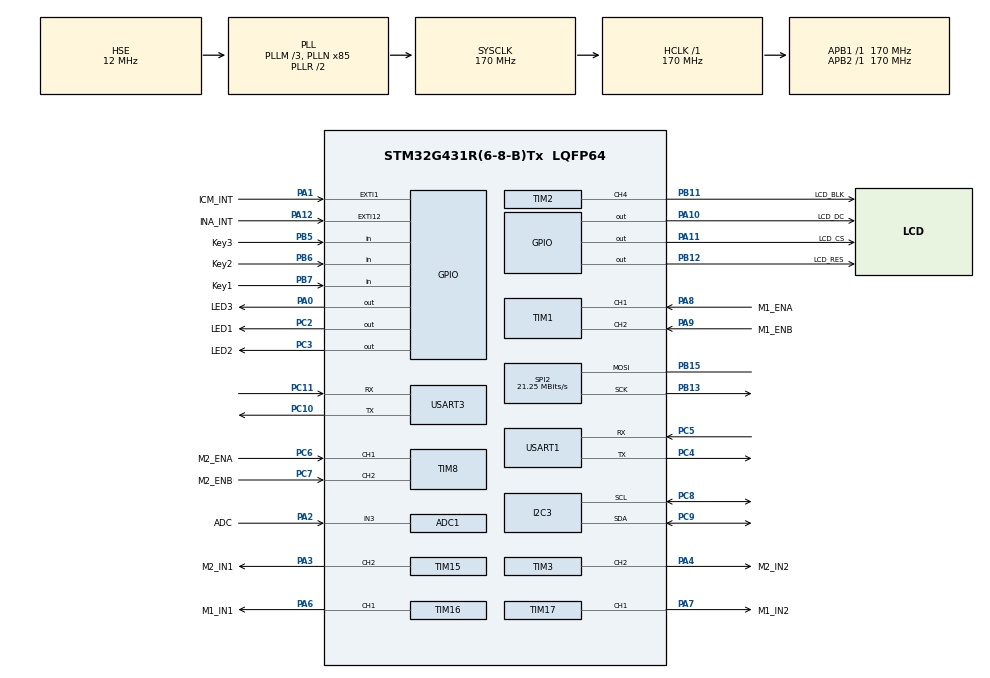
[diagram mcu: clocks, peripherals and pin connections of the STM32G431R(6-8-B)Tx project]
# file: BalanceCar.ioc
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ADC1.Channel-1\#ChannelRegularConversion=ADC_CHANNEL_3
ADC1.NbrOfConversionFlag=1
ADC1.OffsetNumber-1\#ChannelRegularConversion=ADC_OFFSET_NONE
ADC1.Rank-1\#ChannelRegularConversion=1
ADC1.SamplingTime-1\#ChannelRegularConversion=ADC_SAMPLETIME_2CYCLES_5
ADC1.master=1
I2C3.Timing=0x40B285C2
Mcu.Family=STM32G4
Mcu.Name=STM32G431R(6-8-B)Tx
Mcu.Package=LQFP64
NVIC.EXTI15_10_IRQn=true\:1\:0\:true\:false\:true\:true\:true\:true
NVIC.EXTI1_IRQn=true\:1\:0\:true\:false\:true\:true\:true\:true
NVIC.PriorityGroup=NVIC_PRIORITYGROUP_4
PA0.GPIO_Label=LED3
PA0.Signal=GPIO_Output
PA1.GPIO_Label=ICM_INT
PA1.Signal=GPXTI1
PA10.GPIO_Label=LCD_DC
PA10.Signal=GPIO_Output
PA11.GPIO_Label=LCD_CS
PA11.Signal=GPIO_Output
PA12.GPIO_Label=INA_INT
PA12.Signal=GPXTI12
PA13.Mode=Serial_Wire
PA13.Signal=SYS_JTMS-SWDIO
PA14.Mode=Serial_Wire
PA14.Signal=SYS_JTCK-SWCLK
PA2.GPIO_Label=ADC
PA2.Mode=IN3-Single-Ended
PA2.Signal=ADC1_IN3
PA3.GPIO_Label=M2_IN1
PA3.Signal=S_TIM15_CH2
PA4.GPIO_Label=M2_IN2
PA4.Signal=S_TIM3_CH2
PA6.GPIO_Label=M1_IN1
PA6.Signal=S_TIM16_CH1
PA7.GPIO_Label=M1_IN2
PA7.Signal=S_TIM17_CH1
PA8.GPIO_Label=M1_ENA
PA8.Signal=S_TIM1_CH1
PA9.GPIO_Label=M1_ENB
PA9.Signal=S_TIM1_CH2
PB11.GPIO_Label=LCD_BLK
PB11.Signal=S_TIM2_CH4
PB12.GPIO_Label=LCD_RES
PB12.Signal=GPIO_Output
PB13.Mode=Simplex_Bidirectional_Master
PB13.Signal=SPI2_SCK
PB15.Mode=Simplex_Bidirectional_Master
PB15.Signal=SPI2_MOSI
PB5.GPIO_Label=Key3
PB5.GPIO_PuPd=GPIO_PULLUP
PB5.Signal=GPIO_Input
PB6.GPIO_Label=Key2
PB6.GPIO_PuPd=GPIO_PULLUP
PB6.Signal=GPIO_Input
PB7.GPIO_Label=Key1
PB7.GPIO_PuPd=GPIO_PULLUP
PB7.Signal=GPIO_Input
PC10.Mode=Asynchronous
PC10.Signal=USART3_TX
PC11.Mode=Asynchronous
PC11.Signal=USART3_RX
PC2.GPIO_Label=LED1
PC2.Signal=GPIO_Output
PC3.GPIO_Label=LED2
PC3.Signal=GPIO_Output
PC4.Mode=Asynchronous
PC4.Signal=USART1_TX
PC5.Mode=Asynchronous
PC5.Signal=USART1_RX
PC6.GPIO_Label=M2_ENA
PC6.Signal=S_TIM8_CH1
PC7.GPIO_Label=M2_ENB
PC7.Signal=S_TIM8_CH2
PC8.Mode=I2C
PC8.Signal=I2C3_SCL
PC9.Mode=I2C
PC9.Signal=I2C3_SDA
PF0-OSC_IN.Mode=HSE-External-Oscillator
PF0-OSC_IN.Signal=RCC_OSC_IN
PF1-OSC_OUT.Mode=HSE-External-Oscillator
PF1-OSC_OUT.Signal=RCC_OSC_OUT
ProjectManager.HeapSize=0x200
ProjectManager.StackSize=0x400
ProjectManager.TargetToolchain=MDK-ARM V5.32
RCC.ADC12Freq_Value=170000000
RCC.AHBFreq_Value=170000000
RCC.APB1Freq_Value=170000000
RCC.APB1TimFreq_Value=170000000
RCC.APB2Freq_Value=170000000
RCC.APB2TimFreq_Value=170000000
RCC.CortexFreq_Value=170000000
RCC.EXTERNAL_CLOCK_VALUE=12288000
RCC.HCLKFreq_Value=170000000
RCC.HSE_VALUE=12000000
RCC.HSI48_VALUE=48000000
RCC.HSI_VALUE=16000000
RCC.LSE_VALUE=32768
RCC.PLLM=RCC_PLLM_DIV3
RCC.PLLN=85
RCC.PLLSourceVirtual=RCC_PLLSOURCE_HSE
RCC.SYSCLKFreq_VALUE=170000000
RCC.SYSCLKSource=RCC_SYSCLKSOURCE_PLLCLK
RCC.USBFreq_Value=170000000
RCC.VCOOutputFreq_Value=340000000
SH.S_TIM15_CH2.0=TIM15_CH2,PWM Generation2 CH2
SH.S_TIM16_CH1.0=TIM16_CH1,PWM Generation1 CH1
SH.S_TIM17_CH1.0=TIM17_CH1,PWM Generation1 CH1
SH.S_TIM1_CH1.0=TIM1_CH1,Encoder_Interface
SH.S_TIM1_CH2.0=TIM1_CH2,Encoder_Interface
SH.S_TIM2_CH4.0=TIM2_CH4,PWM Generation4 CH4
SH.S_TIM3_CH2.0=TIM3_CH2,PWM Generation2 CH2
SH.S_TIM8_CH1.0=TIM8_CH1,Encoder_Interface
SH.S_TIM8_CH2.0=TIM8_CH2,Encoder_Interface
SPI2.BaudRatePrescaler=SPI_BAUDRATEPRESCALER_8
SPI2.CalculateBaudRate=21.25 MBits/s
SPI2.Direction=SPI_DIRECTION_1LINE
SPI2.Mode=SPI_MODE_MASTER
SPI2.VirtualType=VM_MASTER
TIM1.EncoderMode=TIM_ENCODERMODE_TI12
TIM15.Channel-PWM\ Generation2\ CH2=TIM_CHANNEL_2
TIM15.PeriodNoDither=99
TIM15.Prescaler=16
TIM16.Channel=TIM_CHANNEL_1
TIM16.PeriodNoDither=99
TIM16.Prescaler=16
TIM17.Channel=TIM_CHANNEL_1
TIM17.PeriodNoDither=99
TIM17.Prescaler=16
TIM2.Channel-PWM\ Generation4\ CH4=TIM_CHANNEL_4
TIM2.PeriodNoDither=99
TIM2.Prescaler=16
TIM3.Channel-PWM\ Generation2\ CH2=TIM_CHANNEL_2
TIM3.PeriodNoDither=99
TIM3.Prescaler=16
TIM8.EncoderMode=TIM_ENCODERMODE_TI12
USART1.VirtualMode-Asynchronous=VM_ASYNC
USART3.VirtualMode-Asynchronous=VM_ASYNC
VP_SYS_VS_DBSignals.Mode=DisableDeadBatterySignals
VP_TIM16_VS_ClockSourceINT.Mode=Enable_Timer
VP_TIM17_VS_ClockSourceINT.Mode=Enable_Timer
board=custom

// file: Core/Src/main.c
/* USER CODE BEGIN Header */
/**
  ******************************************************************************
  * @file           : main.c
  * @brief          : Main program body
  ******************************************************************************
  * @attention
  *
  * Copyright (c) 2025 STMicroelectronics.
  * All rights reserved.
  *
  * This software is licensed under terms that can be found in the LICENSE file
  * in the root directory of this software component.
  * If no LICENSE file comes with this software, it is provided AS-IS.
  *
  ******************************************************************************
  */
  /* USER CODE END Header */
  /* Includes ------------------------------------------------------------------*/
#include "main.h"
#include "adc.h"
#include "i2c.h"
#include "spi.h"
#include "tim.h"
#include "usart.h"
#include "gpio.h"

/* USER CODE BEGIN Includes */
#include "icm42688p.h"
#include "ina226.h"
#include "motor.h"
#include "encoder.h"
#include "eeprom.h"
#include "esp32.h"
#include "filter.h"
#include "control.h"
/* USER CODE END Includes */

/* USER CODE BEGIN PV */
ICM42688_Data_t imu_data;
/* USER CODE END PV */

void SystemClock_Config(void);

int main(void)
{

    /* MCU Configuration--------------------------------------------------------*/

    /* Reset of all peripherals, Initializes the Flash interface and the Systick. */
    HAL_Init();

    /* Configure the system clock */
    SystemClock_Config();

    /* Initialize all configured peripherals */
    MX_GPIO_Init();
    MX_ADC1_Init();
    MX_I2C3_Init();
    MX_SPI2_Init();
    MX_TIM1_Init();
    MX_TIM2_Init();
    MX_TIM3_Init();
    MX_TIM8_Init();
    MX_TIM15_Init();
    MX_TIM16_Init();
    MX_TIM17_Init();
    MX_USART1_UART_Init();
    MX_USART3_UART_Init();
    /* USER CODE BEGIN 2 */
    Motor_Enable();
    Encoder_Init();
    ICM42688_Init(ICM42688_AFS_8G, ICM42688_AODR_500HZ, ICM42688_GFS_1000DPS, ICM42688_GODR_500HZ);
    /* USER CODE END 2 */

    /* Infinite loop */
    while (1)
    {

    }
}

void SystemClock_Config(void)
{
    RCC_OscInitTypeDef RCC_OscInitStruct = { 0 };
    RCC_ClkInitTypeDef RCC_ClkInitStruct = { 0 };

    /** Configure the main internal regulator output voltage
    */
    HAL_PWREx_ControlVoltageScaling(PWR_REGULATOR_VOLTAGE_SCALE1_BOOST);

    /** Initializes the RCC Oscillators according to the specified parameters
    * in the RCC_OscInitTypeDef structure.
    */
    RCC_OscInitStruct.OscillatorType = RCC_OSCILLATORTYPE_HSE;
    RCC_OscInitStruct.HSEState = RCC_HSE_ON;
    RCC_OscInitStruct.PLL.PLLState = RCC_PLL_ON;
    RCC_OscInitStruct.PLL.PLLSource = RCC_PLLSOURCE_HSE;
    RCC_OscInitStruct.PLL.PLLM = RCC_PLLM_DIV3;
    RCC_OscInitStruct.PLL.PLLN = 85;
    RCC_OscInitStruct.PLL.PLLP = RCC_PLLP_DIV2;
    RCC_OscInitStruct.PLL.PLLQ = RCC_PLLQ_DIV2;
    RCC_OscInitStruct.PLL.PLLR = RCC_PLLR_DIV2;
    if (HAL_RCC_OscConfig(&RCC_OscInitStruct) != HAL_OK)
    {
        Error_Handler();
    }

    /** Initializes the CPU, AHB and APB buses clocks
    */
    RCC_ClkInitStruct.ClockType = RCC_CLOCKTYPE_HCLK | RCC_CLOCKTYPE_SYSCLK
        | RCC_CLOCKTYPE_PCLK1 | RCC_CLOCKTYPE_PCLK2;
    RCC_ClkInitStruct.SYSCLKSource = RCC_SYSCLKSOURCE_PLLCLK;
    RCC_ClkInitStruct.AHBCLKDivider = RCC_SYSCLK_DIV1;
    RCC_ClkInitStruct.APB1CLKDivider = RCC_HCLK_DIV1;
    RCC_ClkInitStruct.APB2CLKDivider = RCC_HCLK_DIV1;

    if (HAL_RCC_ClockConfig(&RCC_ClkInitStruct, FLASH_LATENCY_4) != HAL_OK)
    {
        Error_Handler();
    }
}

void Error_Handler(void)
{
    __disable_irq();
    while (1)
    {
    }
}
